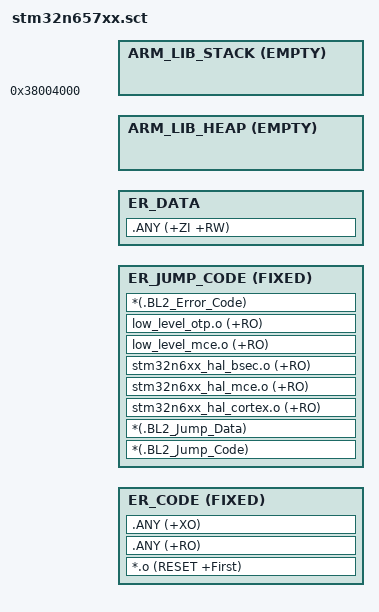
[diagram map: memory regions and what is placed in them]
#! armclang --target=arm-arm-none-eabi -march=armv8-m.main -E -xc

/*
 * Copyright (c) 2017-2018 Arm Limited. All rights reserved.
 *
 * Licensed under the Apache License, Version 2.0 (the "License");
 * you may not use this file except in compliance with the License.
 * You may obtain a copy of the License at
 *
 *     http://www.apache.org/licenses/LICENSE-2.0
 *
 * Unless required by applicable law or agreed to in writing, software
 * distributed under the License is distributed on an "AS IS" BASIS,
 * WITHOUT WARRANTIES OR CONDITIONS OF ANY KIND, either express or implied.
 * See the License for the specific language governing permissions and
 * limitations under the License.
 */

#include "region_defs.h"

LR_CODE BL2_CODE_START {
    ER_CODE (BL2_CODE_START) FIXED (BL2_CODE_SIZE) {
        *.o (RESET +First)
        .ANY (+RO)
        .ANY (+XO)
    }

    ER_JUMP_CODE (BL2_JUMP_CODE_START) FIXED (BL2_JUMP_CODE_SIZE) {
        *(.BL2_Jump_Code)
        *(.BL2_Jump_Data)
        stm32n6xx_hal_cortex.o (+RO)
        stm32n6xx_hal_mce.o (+RO)
        stm32n6xx_hal_bsec.o (+RO)
        low_level_mce.o (+RO)
        low_level_otp.o (+RO)
        *(.BL2_Error_Code)
    }

    ER_DATA (BL2_DATA_START) (BL2_DATA_SIZE-BL2_HEAP_SIZE) {
        .ANY (+ZI +RW)
    }

    ARM_LIB_HEAP +0 ALIGN 32 EMPTY BL2_HEAP_SIZE {
    }

    /* MSP */
    ARM_LIB_STACK (0x38004000) EMPTY BL2_MSP_STACK_SIZE {
    }
}
